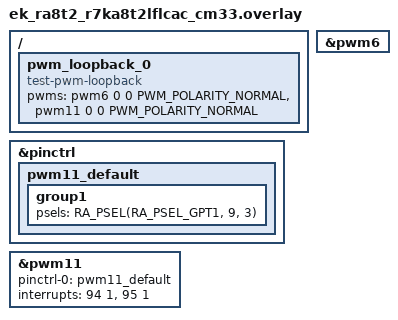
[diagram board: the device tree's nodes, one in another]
/*
 * Copyright (c) 2026 Renesas Electronics Corporation
 * SPDX-License-Identifier: Apache-2.0
 */

#include <zephyr/dt-bindings/pwm/pwm.h>
#include <zephyr/dt-bindings/pwm/ra_pwm.h>

/ {
	pwm_loopback_0 {
		compatible = "test-pwm-loopback";
		/* first index must be a 32-Bit timer */
		pwms = <&pwm6 0 0 PWM_POLARITY_NORMAL>,
		       <&pwm11 0 0 PWM_POLARITY_NORMAL>;
	};
};

&pinctrl {
	pwm11_default: pwm11_default {
		group1 {
			/* GTIOC11A */
			psels = <RA_PSEL(RA_PSEL_GPT1, 9, 3)>;
		};
	};
};

&pwm11 {
	pinctrl-0 = <&pwm11_default>;
	pinctrl-names = "default";
	interrupts = <94 1>, <95 1>;
	interrupt-names = "gtioca", "overflow";
	status = "okay";
};

&pwm6 {
	status = "okay";
};
